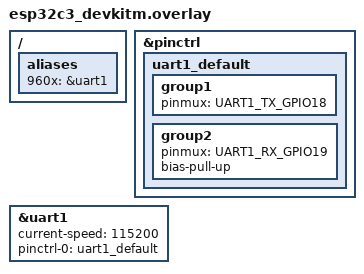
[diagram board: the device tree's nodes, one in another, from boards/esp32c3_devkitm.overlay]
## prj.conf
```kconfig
#CONFIG_FLASH=y
CONFIG_PRINTK=y
#CONFIG_SERIAL=y

# for QEMU
CONFIG_QEMU_ICOUNT=n

#CONFIG_ASSERT=y
#CONFIG_FILE_SYSTEM=y

# If picolibc is used, CONFIG_POSIX_API is required since
# the toolchain and also the module build only tinystdio module
# which relies on POSIX API 
CONFIG_PICOLIBC=y
CONFIG_POSIX_API=y
CONFIG_POSIX_NETWORKING=y

#CONFIG_REQUIRES_FLOAT_PRINTF=y
#CONFIG_NEWLIB_LIBC_FLOAT_PRINTF=y
#CONFIG_NEWLIB_LIBC_FLOAT_SCANF=y

CONFIG_MAIN_STACK_SIZE=16384

## Memory
#CONFIG_HEAP_MEM_POOL_SIZE=2194304
CONFIG_COMMON_LIBC_MALLOC_ARENA_SIZE=262144
# CONFIG_HEAP_MEM_POOL_SIZE=150000
# CONFIG_HEAP_MEM_POOL_SIZE=16384

CONFIG_MAIN_THREAD_PRIORITY=15

# Logging
CONFIG_LOG=y
#CONFIG_LOG_PROCESS_THREAD_PRIORITY=0
#CONFIG_LOG_PROCESS_THREAD_CUSTOM_PRIORITY=y
CONFIG_LOG_PROCESS_TRIGGER_THRESHOLD=1

CONFIG_LOG_MAX_LEVEL=3
CONFIG_LOG_DEFAULT_LEVEL=3
CONFIG_LOG_BACKEND_SHOW_COLOR=y
CONFIG_LOG_BACKEND_FORMAT_TIMESTAMP=n

CONFIG_LUA=y
CONFIG_LUA_PRINTK=y
CONFIG_LUA_SOCKET=y

CONFIG_NETWORKING=y
CONFIG_NET_TCP=y
CONFIG_NET_UDP=y
CONFIG_NET_IPV6=n
CONFIG_NET_IPV4=y
CONFIG_NET_SOCKETS=y

CONFIG_NET_CONFIG_SETTINGS=y
CONFIG_NET_CONFIG_MY_IPV4_ADDR="192.0.2.1"

CONFIG_DNS_RESOLVER=y
```

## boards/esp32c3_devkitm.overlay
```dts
/ {

  aliases {
    960x = &uart1;
  };

};

&pinctrl {

  uart1_default: uart1_default {
		
    group1 {
			pinmux = <UART1_TX_GPIO18>;
		};

		group2 {
			pinmux = <UART1_RX_GPIO19>;
			bias-pull-up;
		};

	};

};

&uart1 {
	status = "okay";
	current-speed = <115200>;
	pinctrl-0 = <&uart1_default>;
	pinctrl-names = "default";
};
```

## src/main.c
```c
#include <zephyr/device.h>
#include <zephyr/drivers/uart.h>
#include <zephyr/usb/usb_device.h>
#include <zephyr/storage/disk_access.h>
#include <zephyr/fs/fs.h>
#include <string.h>
#include <stdio.h>
#include <stdlib.h>
#include <math.h>

#include <lauxlib.h>
#include <lualib.h>
#include <luasocket.h>

#include "luac.h"

LOG_MODULE_REGISTER(app);

// For reference
// https://www.lua.org/pil/24.1.html
// https://docs.zephyrproject.org/latest/contribute/bin_blobs.html

int main(void) {

  static lua_State * L;

  L = luaL_newstate();

  luaL_openlibs(L);

  luaopen_socket_core(L);
  lua_setglobal(L, "socket");
  
  int error = 
    luaL_loadbuffer(L, g_lua_main, sizeof(g_lua_main), "main") 
    || lua_pcall(L, 0, 0, 0);

  if (error) {
    // lua_tostring() returns and appends 
    // at the same time the value in the stack
    LOG_ERR("%s", lua_tostring(L, -1));
    lua_pop(L, 1); 
  }

  lua_close(L);
  
  return 0;
}
```

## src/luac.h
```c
#ifndef LUA_SOURCE_H_
#define LUA_SOURCE_H_
static const unsigned char g_lua_main[] = {
	#include "lua/main.lbc.h"
};
#endif
```
